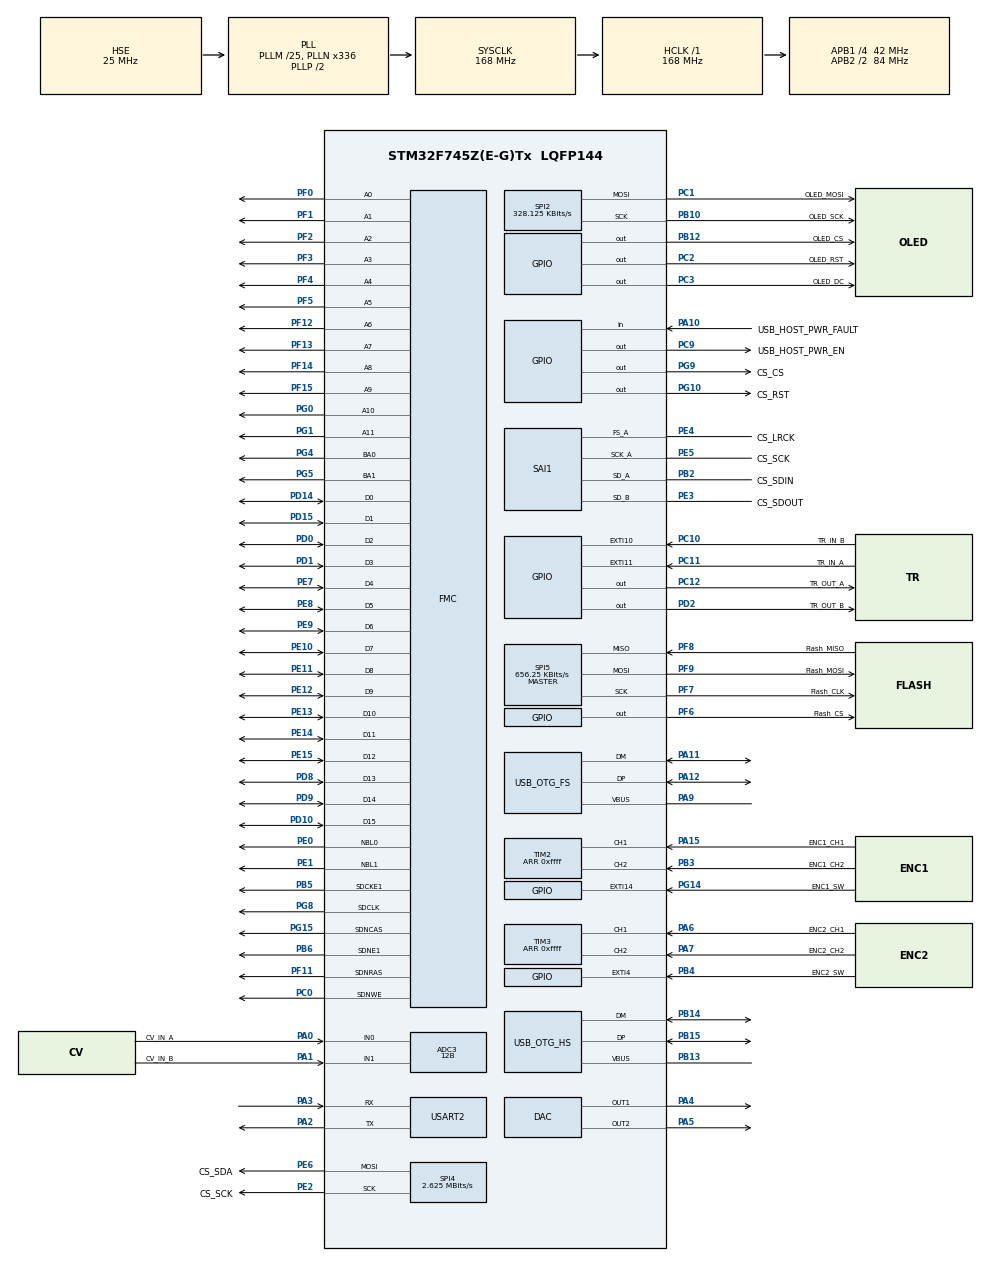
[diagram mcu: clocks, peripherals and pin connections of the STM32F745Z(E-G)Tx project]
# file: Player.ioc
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ADC3.Channel-0\#ChannelRegularConversion=ADC_CHANNEL_0
ADC3.Channel-1\#ChannelRegularConversion=ADC_CHANNEL_1
ADC3.Channel-2\#ChannelRegularConversion=ADC_CHANNEL_0
ADC3.Channel-3\#ChannelRegularConversion=ADC_CHANNEL_1
ADC3.ClockPrescaler=ADC_CLOCK_SYNC_PCLK_DIV8
ADC3.ContinuousConvMode=ENABLE
ADC3.DMAContinuousRequests=ENABLE
ADC3.DataAlign=ADC_DATAALIGN_RIGHT
ADC3.DiscontinuousConvMode=DISABLE
ADC3.EOCSelection=ADC_EOC_SEQ_CONV
ADC3.EnableAnalogWatchDog=false
ADC3.ExternalTrigConv=ADC_SOFTWARE_START
ADC3.ExternalTrigConvEdge=ADC_EXTERNALTRIGCONVEDGE_NONE
ADC3.InjNumberOfConversion=0
ADC3.NbrOfConversion=4
ADC3.NbrOfConversionFlag=1
ADC3.Rank-0\#ChannelRegularConversion=1
ADC3.Rank-1\#ChannelRegularConversion=2
ADC3.Rank-2\#ChannelRegularConversion=3
ADC3.Rank-3\#ChannelRegularConversion=4
ADC3.Resolution=ADC_RESOLUTION_12B
ADC3.SamplingTime-0\#ChannelRegularConversion=ADC_SAMPLETIME_144CYCLES
ADC3.SamplingTime-1\#ChannelRegularConversion=ADC_SAMPLETIME_144CYCLES
ADC3.SamplingTime-2\#ChannelRegularConversion=ADC_SAMPLETIME_144CYCLES
ADC3.SamplingTime-3\#ChannelRegularConversion=ADC_SAMPLETIME_144CYCLES
ADC3.ScanConvMode=ENABLE
DAC.DAC_OutputBuffer=DAC_OUTPUTBUFFER_DISABLE
DAC.DAC_OutputBuffer2=DAC_OUTPUTBUFFER_DISABLE
DAC.DAC_Trigger=DAC_TRIGGER_T6_TRGO
DAC.DAC_Trigger2=DAC_TRIGGER_T6_TRGO
Dma.ADC3.3.Direction=DMA_PERIPH_TO_MEMORY
Dma.ADC3.3.FIFOMode=DMA_FIFOMODE_DISABLE
Dma.ADC3.3.Instance=DMA2_Stream0
Dma.ADC3.3.MemDataAlignment=DMA_MDATAALIGN_HALFWORD
Dma.ADC3.3.MemInc=DMA_MINC_ENABLE
Dma.ADC3.3.Mode=DMA_CIRCULAR
Dma.ADC3.3.PeriphDataAlignment=DMA_PDATAALIGN_HALFWORD
Dma.ADC3.3.PeriphInc=DMA_PINC_DISABLE
Dma.ADC3.3.Priority=DMA_PRIORITY_LOW
Dma.DAC1.1.Direction=DMA_MEMORY_TO_PERIPH
Dma.DAC1.1.FIFOMode=DMA_FIFOMODE_DISABLE
Dma.DAC1.1.Instance=DMA1_Stream5
Dma.DAC1.1.MemDataAlignment=DMA_MDATAALIGN_HALFWORD
Dma.DAC1.1.MemInc=DMA_MINC_ENABLE
Dma.DAC1.1.Mode=DMA_NORMAL
Dma.DAC1.1.PeriphDataAlignment=DMA_PDATAALIGN_HALFWORD
Dma.DAC1.1.PeriphInc=DMA_PINC_DISABLE
Dma.DAC1.1.Priority=DMA_PRIORITY_LOW
Dma.DAC2.2.Direction=DMA_MEMORY_TO_PERIPH
Dma.DAC2.2.FIFOMode=DMA_FIFOMODE_DISABLE
Dma.DAC2.2.Instance=DMA1_Stream6
Dma.DAC2.2.MemDataAlignment=DMA_MDATAALIGN_HALFWORD
Dma.DAC2.2.MemInc=DMA_MINC_ENABLE
Dma.DAC2.2.Mode=DMA_NORMAL
Dma.DAC2.2.PeriphDataAlignment=DMA_PDATAALIGN_HALFWORD
Dma.DAC2.2.PeriphInc=DMA_PINC_DISABLE
Dma.DAC2.2.Priority=DMA_PRIORITY_LOW
Dma.Request0=SPI2_TX
Dma.Request1=DAC1
Dma.Request2=DAC2
Dma.Request3=ADC3
Dma.Request4=SAI1_A
Dma.Request5=SAI1_B
Dma.SAI1_A.4.Direction=DMA_MEMORY_TO_PERIPH
Dma.SAI1_A.4.FIFOMode=DMA_FIFOMODE_DISABLE
Dma.SAI1_A.4.Instance=DMA2_Stream1
Dma.SAI1_A.4.MemDataAlignment=DMA_MDATAALIGN_WORD
Dma.SAI1_A.4.MemInc=DMA_MINC_ENABLE
Dma.SAI1_A.4.Mode=DMA_CIRCULAR
Dma.SAI1_A.4.PeriphDataAlignment=DMA_PDATAALIGN_WORD
Dma.SAI1_A.4.PeriphInc=DMA_PINC_DISABLE
Dma.SAI1_A.4.Priority=DMA_PRIORITY_HIGH
Dma.SAI1_B.5.Direction=DMA_PERIPH_TO_MEMORY
Dma.SAI1_B.5.FIFOMode=DMA_FIFOMODE_DISABLE
Dma.SAI1_B.5.Instance=DMA2_Stream4
Dma.SAI1_B.5.MemDataAlignment=DMA_MDATAALIGN_WORD
Dma.SAI1_B.5.MemInc=DMA_MINC_ENABLE
Dma.SAI1_B.5.Mode=DMA_CIRCULAR
Dma.SAI1_B.5.PeriphDataAlignment=DMA_PDATAALIGN_WORD
Dma.SAI1_B.5.PeriphInc=DMA_PINC_DISABLE
Dma.SAI1_B.5.Priority=DMA_PRIORITY_HIGH
Dma.SPI2_TX.0.Direction=DMA_MEMORY_TO_PERIPH
Dma.SPI2_TX.0.FIFOMode=DMA_FIFOMODE_DISABLE
Dma.SPI2_TX.0.Instance=DMA1_Stream4
Dma.SPI2_TX.0.MemDataAlignment=DMA_MDATAALIGN_BYTE
Dma.SPI2_TX.0.MemInc=DMA_MINC_ENABLE
Dma.SPI2_TX.0.Mode=DMA_NORMAL
Dma.SPI2_TX.0.PeriphDataAlignment=DMA_PDATAALIGN_BYTE
Dma.SPI2_TX.0.PeriphInc=DMA_PINC_DISABLE
Dma.SPI2_TX.0.Priority=DMA_PRIORITY_LOW
FMC.CASLatency1=FMC_SDRAM_CAS_LATENCY_3
FMC.ExitSelfRefreshDelay1=6
FMC.LoadToActiveDelay1=2
FMC.RCDDelay1=2
FMC.RPDelay1=2
FMC.ReadBurst1=FMC_SDRAM_RBURST_ENABLE
FMC.ReadPipeDelay1=FMC_SDRAM_RPIPE_DELAY_0
FMC.RowCycleDelay1=6
FMC.SDClockPeriod1=FMC_SDRAM_CLOCK_PERIOD_2
FMC.SelfRefreshTime1=4
FMC.WriteRecoveryTime1=2
FREERTOS.MEMORY_ALLOCATION=2
FREERTOS.Tasks01=defaultTask,0,128,StartDefaultTask,Default
FREERTOS.configCHECK_FOR_STACK_OVERFLOW=1
FREERTOS.configUSE_MALLOC_FAILED_HOOK=1
FREERTOS.configUSE_MUTEXES=0
FREERTOS.configUSE_PREEMPTION=0
Mcu.Family=STM32F7
Mcu.Name=STM32F745Z(E-G)Tx
Mcu.Package=LQFP144
NVIC.DMA1_Stream4_IRQn=true\:5\:0\:false\:false\:true\:true\:true
NVIC.DMA1_Stream5_IRQn=true\:5\:0\:false\:false\:true\:true\:true
NVIC.DMA1_Stream6_IRQn=true\:5\:0\:false\:false\:true\:true\:true
NVIC.DMA2_Stream0_IRQn=true\:10\:0\:true\:false\:true\:true\:true
NVIC.DMA2_Stream1_IRQn=true\:5\:0\:false\:false\:true\:true\:true
NVIC.DMA2_Stream4_IRQn=true\:5\:0\:false\:false\:true\:true\:true
NVIC.EXTI15_10_IRQn=true\:10\:0\:true\:false\:true\:true\:true
NVIC.EXTI4_IRQn=true\:10\:0\:true\:false\:true\:true\:true
NVIC.OTG_FS_IRQn=true\:10\:0\:true\:false\:true\:true\:true
NVIC.OTG_HS_IRQn=true\:10\:0\:true\:false\:true\:true\:true
NVIC.PriorityGroup=NVIC_PRIORITYGROUP_4
NVIC.SPI2_IRQn=true\:5\:0\:false\:false\:true\:true\:true
NVIC.TIM2_IRQn=true\:10\:0\:true\:false\:true\:true\:true
NVIC.TIM3_IRQn=true\:10\:0\:true\:false\:true\:true\:true
PA0/WKUP.GPIO_Label=CV_IN_A
PA0/WKUP.Signal=ADCx_IN0
PA1.GPIO_Label=CV_IN_B
PA1.Signal=ADCx_IN1
PA10.GPIO_Label=USB_HOST_PWR_FAULT
PA10.Signal=GPIO_Input
PA11.Mode=Host_Only
PA11.Signal=USB_OTG_FS_DM
PA12.Mode=Host_Only
PA12.Signal=USB_OTG_FS_DP
PA13.Mode=Serial_Wire
PA13.Signal=SYS_JTMS-SWDIO
PA14.Mode=Serial_Wire
PA14.Signal=SYS_JTCK-SWCLK
PA15.GPIO_Label=ENC1_CH1
PA15.GPIO_PuPd=GPIO_PULLUP
PA15.Signal=S_TIM2_CH1_ETR
PA2.Mode=Asynchronous
PA2.Signal=USART2_TX
PA3.Mode=Asynchronous
PA3.Signal=USART2_RX
PA4.Signal=COMP_DAC1_group
PA5.Signal=COMP_DAC2_group
PA6.GPIO_Label=ENC2_CH1
PA6.GPIO_PuPd=GPIO_PULLUP
PA6.Signal=S_TIM3_CH1
PA7.GPIO_Label=ENC2_CH2
PA7.GPIO_PuPd=GPIO_PULLUP
PA7.Signal=S_TIM3_CH2
PA9.Mode=Activate_VBUS
PA9.Signal=USB_OTG_FS_VBUS
PB10.GPIO_Label=OLED_SCK
PB10.Mode=TX_Only_Simplex_Unidirect_Master
PB10.Signal=SPI2_SCK
PB12.GPIO_Label=OLED_CS
PB12.Signal=GPIO_Output
PB13.Mode=Activate_VBUS_FS
PB13.Signal=USB_OTG_HS_VBUS
PB14.Mode=Device_Only_FS
PB14.Signal=USB_OTG_HS_DM
PB15.Mode=Device_Only_FS
PB15.Signal=USB_OTG_HS_DP
PB2.GPIO_Label=CS_SDIN
PB2.Mode=SAI_A_AsyncSlave
PB2.Signal=SAI1_SD_A
PB3.GPIO_Label=ENC1_CH2
PB3.GPIO_PuPd=GPIO_PULLUP
PB3.Signal=S_TIM2_CH2
PB4.GPIO_Label=ENC2_SW
PB4.GPIO_ModeDefaultEXTI=GPIO_MODE_IT_FALLING
PB4.GPIO_PuPd=GPIO_PULLUP
PB4.Signal=GPXTI4
PB5.Mode=SdramChipSelect2_1
PB5.Signal=FMC_SDCKE1
PB6.Mode=SdramChipSelect2_1
PB6.Signal=FMC_SDNE1
PC0.Signal=FMC_SDNWE
PC1.GPIO_Label=OLED_MOSI
PC1.Mode=TX_Only_Simplex_Unidirect_Master
PC1.Signal=SPI2_MOSI
PC10.GPIO_Label=TR_IN_B
PC10.GPIO_ModeDefaultEXTI=GPIO_MODE_IT_RISING_FALLING
PC10.GPIO_PuPd=GPIO_PULLUP
PC10.Signal=GPXTI10
PC11.GPIO_Label=TR_IN_A
PC11.GPIO_ModeDefaultEXTI=GPIO_MODE_IT_RISING_FALLING
PC11.GPIO_PuPd=GPIO_PULLUP
PC11.Signal=GPXTI11
PC12.GPIO_Label=TR_OUT_A
PC12.Signal=GPIO_Output
PC2.GPIO_Label=OLED_RST
PC2.Signal=GPIO_Output
PC3.GPIO_Label=OLED_DC
PC3.Signal=GPIO_Output
PC9.GPIO_Label=USB_HOST_PWR_EN
PC9.Signal=GPIO_Output
PD0.Signal=FMC_D2_DA2
PD1.Signal=FMC_D3_DA3
PD10.Signal=FMC_D15_DA15
PD14.Signal=FMC_D0_DA0
PD15.Signal=FMC_D1_DA1
PD2.GPIO_Label=TR_OUT_B
PD2.Signal=GPIO_Output
PD8.Signal=FMC_D13_DA13
PD9.Signal=FMC_D14_DA14
PE0.Signal=FMC_NBL0
PE1.Signal=FMC_NBL1
PE10.Signal=FMC_D7_DA7
PE11.Signal=FMC_D8_DA8
PE12.Signal=FMC_D9_DA9
PE13.Signal=FMC_D10_DA10
PE14.Signal=FMC_D11_DA11
PE15.Signal=FMC_D12_DA12
PE2.GPIO_Label=CS_SCK
PE2.Mode=TX_Only_Simplex_Unidirect_Master
PE2.Signal=SPI4_SCK
PE3.GPIO_Label=CS_SDOUT
PE3.Mode=SAI_B_SyncSlave
PE3.Signal=SAI1_SD_B
PE4.GPIO_Label=CS_LRCK
PE4.Mode=SAI_A_AsyncSlave
PE4.Signal=SAI1_FS_A
PE5.GPIO_Label=CS_SCK
PE5.Mode=SAI_A_AsyncSlave
PE5.Signal=SAI1_SCK_A
PE6.GPIO_Label=CS_SDA
PE6.Mode=TX_Only_Simplex_Unidirect_Master
PE6.Signal=SPI4_MOSI
PE7.Signal=FMC_D4_DA4
PE8.Signal=FMC_D5_DA5
PE9.Signal=FMC_D6_DA6
PF0.Signal=FMC_A0
PF1.Signal=FMC_A1
PF11.Signal=FMC_SDNRAS
PF12.Signal=FMC_A6
PF13.Signal=FMC_A7
PF14.Signal=FMC_A8
PF15.Signal=FMC_A9
PF2.Signal=FMC_A2
PF3.Signal=FMC_A3
PF4.Signal=FMC_A4
PF5.Signal=FMC_A5
PF6.GPIO_Label=Flash_CS
PF6.Signal=GPIO_Output
PF7.GPIO_Label=Flash_CLK
PF7.Mode=Full_Duplex_Master
PF7.Signal=SPI5_SCK
PF8.GPIO_Label=Flash_MISO
PF8.Mode=Full_Duplex_Master
PF8.Signal=SPI5_MISO
PF9.GPIO_Label=Flash_MOSI
PF9.Mode=Full_Duplex_Master
PF9.Signal=SPI5_MOSI
PG0.Signal=FMC_A10
PG1.Signal=FMC_A11
PG10.GPIO_Label=CS_RST
PG10.Signal=GPIO_Output
PG14.GPIO_Label=ENC1_SW
PG14.GPIO_ModeDefaultEXTI=GPIO_MODE_IT_FALLING
PG14.GPIO_PuPd=GPIO_PULLUP
PG14.Signal=GPXTI14
PG15.Signal=FMC_SDNCAS
PG4.Signal=FMC_A14_BA0
PG5.Signal=FMC_A15_BA1
PG8.Signal=FMC_SDCLK
PG9.GPIO_Label=CS_CS
PG9.Signal=GPIO_Output
PH0/OSC_IN.Mode=HSE-External-Oscillator
PH0/OSC_IN.Signal=RCC_OSC_IN
PH1/OSC_OUT.Mode=HSE-External-Oscillator
PH1/OSC_OUT.Signal=RCC_OSC_OUT
ProjectManager.HeapSize=0x400
ProjectManager.StackSize=0x200
ProjectManager.TargetToolchain=MDK-ARM V4
RCC.AHBFreq_Value=168000000
RCC.APB1CLKDivider=RCC_HCLK_DIV4
RCC.APB1Freq_Value=42000000
RCC.APB1TimFreq_Value=84000000
RCC.APB2CLKDivider=RCC_HCLK_DIV2
RCC.APB2Freq_Value=84000000
RCC.APB2TimFreq_Value=168000000
RCC.CortexFreq_Value=168000000
RCC.HCLKFreq_Value=168000000
RCC.HSE_VALUE=25000000
RCC.HSI_VALUE=16000000
RCC.LSE_VALUE=32768
RCC.PLLM=25
RCC.PLLN=336
RCC.PLLQ=7
RCC.PLLSAIN=100
RCC.SYSCLKFreq_VALUE=168000000
RCC.SYSCLKSource=RCC_SYSCLKSOURCE_PLLCLK
RCC.USBFreq_Value=48000000
RCC.VCOOutputFreq_Value=336000000
SAI1.AudioMode-SAI_A_AsyncSlave=SAI_MODESLAVE_TX
SAI1.AudioMode-SAI_B_SyncSlave=SAI_MODESLAVE_RX
SAI1.BasicDataSize-SAI_A_AsyncSlave=SAI_PROTOCOL_DATASIZE_24BIT
SAI1.BasicDataSize-SAI_B_SyncSlave=SAI_PROTOCOL_DATASIZE_24BIT
SAI1.InitProtocol-SAI_A_AsyncSlave=Enable
SAI1.InitProtocol-SAI_B_SyncSlave=Enable
SAI1.Instance-SAI_A_AsyncSlave=SAI$Index_Block_A
SAI1.Instance-SAI_B_SyncSlave=SAI$Index_Block_B
SAI1.Synchro-SAI_A_AsyncSlave=SAI_ASYNCHRONOUS
SAI1.Synchro-SAI_B_SyncSlave=SAI_SYNCHRONOUS
SAI1.TriState-SAI_A_AsyncSlave=SAI_OUTPUT_NOTRELEASED
SAI1.VirtualMode-SAI_A_AsyncSlave=VM_SLAVE
SAI1.VirtualMode-SAI_B_SyncSlave=VM_SLAVE
SAI1.VirtualProtocol-SAI_A_BASIC=VM_BASIC_PROTOCOL
SAI1.VirtualProtocol-SAI_B_BASIC=VM_BASIC_PROTOCOL
SH.ADCx_IN0.0=ADC1_IN0
SH.ADCx_IN0.1=ADC3_IN0,IN0
SH.ADCx_IN1.0=ADC1_IN1
SH.ADCx_IN1.1=ADC3_IN1,IN1
SH.COMP_DAC1_group.0=DAC_OUT1,DAC_OUT1
SH.COMP_DAC2_group.0=DAC_OUT2,DAC_OUT2
SH.FMC_A0.0=FMC_A0,12b-sda1
SH.FMC_A1.0=FMC_A1,12b-sda1
SH.FMC_A10.0=FMC_A10,12b-sda1
SH.FMC_A11.0=FMC_A11,12b-sda1
SH.FMC_A14_BA0.0=FMC_BA0,FourSdramBanks1
SH.FMC_A15_BA1.0=FMC_BA1,FourSdramBanks1
SH.FMC_A2.0=FMC_A2,12b-sda1
SH.FMC_A3.0=FMC_A3,12b-sda1
SH.FMC_A4.0=FMC_A4,12b-sda1
SH.FMC_A5.0=FMC_A5,12b-sda1
SH.FMC_A6.0=FMC_A6,12b-sda1
SH.FMC_A7.0=FMC_A7,12b-sda1
SH.FMC_A8.0=FMC_A8,12b-sda1
SH.FMC_A9.0=FMC_A9,12b-sda1
SH.FMC_D0_DA0.0=FMC_D0,sd-16b-d1
SH.FMC_D10_DA10.0=FMC_D10,sd-16b-d1
SH.FMC_D11_DA11.0=FMC_D11,sd-16b-d1
SH.FMC_D12_DA12.0=FMC_D12,sd-16b-d1
SH.FMC_D13_DA13.0=FMC_D13,sd-16b-d1
SH.FMC_D14_DA14.0=FMC_D14,sd-16b-d1
SH.FMC_D15_DA15.0=FMC_D15,sd-16b-d1
SH.FMC_D1_DA1.0=FMC_D1,sd-16b-d1
SH.FMC_D2_DA2.0=FMC_D2,sd-16b-d1
SH.FMC_D3_DA3.0=FMC_D3,sd-16b-d1
SH.FMC_D4_DA4.0=FMC_D4,sd-16b-d1
SH.FMC_D5_DA5.0=FMC_D5,sd-16b-d1
SH.FMC_D6_DA6.0=FMC_D6,sd-16b-d1
SH.FMC_D7_DA7.0=FMC_D7,sd-16b-d1
SH.FMC_D8_DA8.0=FMC_D8,sd-16b-d1
SH.FMC_D9_DA9.0=FMC_D9,sd-16b-d1
SH.FMC_NBL0.0=FMC_NBL0,Sd2ByteEnable1
SH.FMC_NBL1.0=FMC_NBL1,Sd2ByteEnable1
SH.FMC_SDCLK.0=FMC_SDCLK,12b-sda1
SH.FMC_SDNCAS.0=FMC_SDNCAS,12b-sda1
SH.FMC_SDNRAS.0=FMC_SDNRAS,12b-sda1
SH.FMC_SDNWE.0=FMC_SDNWE,12b-sda1
SH.S_TIM2_CH1_ETR.0=TIM2_CH1,Encoder_Interface
SH.S_TIM2_CH2.0=TIM2_CH2,Encoder_Interface
SH.S_TIM3_CH1.0=TIM3_CH1,Encoder_Interface
SH.S_TIM3_CH2.0=TIM3_CH2,Encoder_Interface
SPI2.BaudRatePrescaler=SPI_BAUDRATEPRESCALER_128
SPI2.CalculateBaudRate=328.125 KBits/s
SPI2.DataSize=SPI_DATASIZE_8BIT
SPI2.Direction=SPI_DIRECTION_2LINES
SPI2.Mode=SPI_MODE_MASTER
SPI2.VirtualType=VM_MASTER
SPI4.BaudRatePrescaler=SPI_BAUDRATEPRESCALER_32
SPI4.CalculateBaudRate=2.625 MBits/s
SPI4.DataSize=SPI_DATASIZE_8BIT
SPI4.Direction=SPI_DIRECTION_2LINES
SPI4.Mode=SPI_MODE_MASTER
SPI4.NSSPMode=SPI_NSS_PULSE_DISABLE
SPI4.VirtualType=VM_MASTER
SPI5.BaudRatePrescaler=SPI_BAUDRATEPRESCALER_128
SPI5.CalculateBaudRate=656.25 KBits/s
SPI5.DataSize=SPI_DATASIZE_8BIT
SPI5.Direction=SPI_DIRECTION_2LINES
SPI5.Mode=SPI_MODE_MASTER
SPI5.VirtualType=VM_MASTER
TIM2.EncoderMode=TIM_ENCODERMODE_TI12
TIM2.Period=0xffff
TIM3.EncoderMode=TIM_ENCODERMODE_TI12
TIM3.Period=0xffff
TIM6.Period=8
TIM6.Prescaler=3500
TIM6.TIM_MasterOutputTrigger=TIM_TRGO_UPDATE
USART2.VirtualMode-Asynchronous=VM_ASYNC
USART2.WordLength=WORDLENGTH_8B
USB_DEVICE.CLASS_NAME_HS=AUDIO
USB_DEVICE.MANUFACTURER_STRING-AUDIO_HS=Rebel Technology
USB_DEVICE.PID_AUDIO_HS=0xDADA
USB_DEVICE.PRODUCT_STRING_AUDIO_HS=OWL-MIDI
USB_DEVICE.SERIALNUMBER_STRING_AUDIO_HS=00000000010E
USB_DEVICE.USBD_AUDIO_FREQ-AUDIO_HS=48000
USB_DEVICE.USBD_LPM_ENABLED-AUDIO_HS=0
USB_DEVICE.VID-AUDIO_HS=0x1209
USB_DEVICE.VirtualMode-AUDIO_HS=Audio
USB_DEVICE.VirtualModeHS=Audio_HS
USB_HOST.USBH_HandleTypeDef-AUDIO_FS=hUsbHostFS
USB_HOST.VirtualModeFS=Audio
USB_OTG_FS.VirtualMode=Host_Only
USB_OTG_FS.phy_itface=HCD_PHY_EMBEDDED
USB_OTG_HS.VirtualMode-Device_Only_FS=Device_Only_FS
VP_FREERTOS_VS_ENABLE.Mode=Enabled
VP_SAI1_VP_$IpInstance_SAIA_SAI_BASIC.Mode=SAI_A_BASIC
VP_SAI1_VP_$IpInstance_SAIB_SAI_BASIC.Mode=SAI_B_BASIC
VP_TIM6_VS_ClockSourceINT.Mode=Enable_Timer
VP_USB_DEVICE_VS_USB_DEVICE_AUDIO_HS.Mode=AUDIO_HS
VP_USB_HOST_VS_USB_HOST_AUDIO_FS.Mode=AUDIO_FS
board=Player

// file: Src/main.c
/**
  ******************************************************************************
  * File Name          : main.c
  * Description        : Main program body
  ******************************************************************************
  * This notice applies to any and all portions of this file
  * that are not between comment pairs USER CODE BEGIN and
  * USER CODE END. Other portions of this file, whether
  * inserted by the user or by software development tools
  * are owned by their respective copyright owners.
  *
  * Copyright (c) 2017 STMicroelectronics International N.V.
  * All rights reserved.
  *
  * Redistribution and use in source and binary forms, with or without
  * modification, are permitted, provided that the following conditions are met:
  *
  * 1. Redistribution of source code must retain the above copyright notice,
  *    this list of conditions and the following disclaimer.
  * 2. Redistributions in binary form must reproduce the above copyright notice,
  *    this list of conditions and the following disclaimer in the documentation
  *    and/or other materials provided with the distribution.
  * 3. Neither the name of STMicroelectronics nor the names of other
  *    contributors to this software may be used to endorse or promote products
  *    derived from this software without specific written permission.
  * 4. This software, including modifications and/or derivative works of this
  *    software, must execute solely and exclusively on microcontroller or
  *    microprocessor devices manufactured by or for STMicroelectronics.
  * 5. Redistribution and use of this software other than as permitted under
  *    this license is void and will automatically terminate your rights under
  *    this license.
  *
  * THIS SOFTWARE IS PROVIDED BY STMICROELECTRONICS AND CONTRIBUTORS "AS IS"
  * AND ANY EXPRESS, IMPLIED OR STATUTORY WARRANTIES, INCLUDING, BUT NOT
  * LIMITED TO, THE IMPLIED WARRANTIES OF MERCHANTABILITY, FITNESS FOR A
  * PARTICULAR PURPOSE AND NON-INFRINGEMENT OF THIRD PARTY INTELLECTUAL PROPERTY
  * RIGHTS ARE DISCLAIMED TO THE FULLEST EXTENT PERMITTED BY LAW. IN NO EVENT
  * SHALL STMICROELECTRONICS OR CONTRIBUTORS BE LIABLE FOR ANY DIRECT, INDIRECT,
  * INCIDENTAL, SPECIAL, EXEMPLARY, OR CONSEQUENTIAL DAMAGES (INCLUDING, BUT NOT
  * LIMITED TO, PROCUREMENT OF SUBSTITUTE GOODS OR SERVICES; LOSS OF USE, DATA,
  * OR PROFITS; OR BUSINESS INTERRUPTION) HOWEVER CAUSED AND ON ANY THEORY OF
  * LIABILITY, WHETHER IN CONTRACT, STRICT LIABILITY, OR TORT (INCLUDING
  * NEGLIGENCE OR OTHERWISE) ARISING IN ANY WAY OUT OF THE USE OF THIS SOFTWARE,
  * EVEN IF ADVISED OF THE POSSIBILITY OF SUCH DAMAGE.
  *
  ******************************************************************************
  */
#include "main.h"
#include "stm32f7xx_hal.h"
#include "cmsis_os.h"
#include "usb_device.h"
#include "usb_host.h"

/* USER CODE BEGIN Includes */
#include "HAL_Triggers.h"
#include "HAL_Encoders.h"
#include "HAL_CV_IO.h"
#include "sdram.h"
/* USER CODE END Includes */

ADC_HandleTypeDef hadc3;
DMA_HandleTypeDef hdma_adc3;

DAC_HandleTypeDef hdac;
DMA_HandleTypeDef hdma_dac1;
DMA_HandleTypeDef hdma_dac2;

SAI_HandleTypeDef hsai_BlockA1;
SAI_HandleTypeDef hsai_BlockB1;
DMA_HandleTypeDef hdma_sai1_a;
DMA_HandleTypeDef hdma_sai1_b;

SPI_HandleTypeDef hspi2;
SPI_HandleTypeDef hspi4;
SPI_HandleTypeDef hspi5;
DMA_HandleTypeDef hdma_spi2_tx;

TIM_HandleTypeDef htim2;
TIM_HandleTypeDef htim3;
TIM_HandleTypeDef htim6;

UART_HandleTypeDef huart2;

SDRAM_HandleTypeDef hsdram1;

osThreadId defaultTaskHandle;

/* USER CODE BEGIN PV */
/* Private variables ---------------------------------------------------------*/

/* USER CODE END PV */

void SystemClock_Config(void);
static void MX_GPIO_Init(void);
static void MX_DMA_Init(void);
static void MX_DAC_Init(void);
static void MX_FMC_Init(void);
static void MX_SAI1_Init(void);
static void MX_SPI2_Init(void);
static void MX_SPI5_Init(void);
static void MX_TIM2_Init(void);
static void MX_TIM3_Init(void);
static void MX_USART2_UART_Init(void);
static void MX_SPI4_Init(void);
static void MX_TIM6_Init(void);
static void MX_ADC3_Init(void);
void StartDefaultTask(void const * argument);

/* USER CODE BEGIN PFP */
/* Private function prototypes -----------------------------------------------*/

void setup(void);
void loop(void);
void MX_USB_HOST_Process(void);

/* USER CODE END PFP */

int main(void)
{

  /* USER CODE BEGIN 1 */
  /* Configure the MPU attributes as Write Back */
  MPU_Config();

  /* USER CODE END 1 */

  /* MCU Configuration----------------------------------------------------------*/

  /* Reset of all peripherals, Initializes the Flash interface and the Systick. */
  HAL_Init();

  /* Configure the system clock */
  SystemClock_Config();

  /* Initialize all configured peripherals */
  MX_GPIO_Init();
  MX_DMA_Init();
  MX_DAC_Init();
  MX_FMC_Init();
  MX_SAI1_Init();
  MX_SPI2_Init();
  MX_SPI5_Init();
  MX_TIM2_Init();
  MX_TIM3_Init();
  MX_USART2_UART_Init();
  MX_SPI4_Init();
  MX_TIM6_Init();
  MX_ADC3_Init();

  /* USER CODE BEGIN 2 */
  HAL_SAI_DeInit(&hsai_BlockA1);
  HAL_SAI_DeInit(&hsai_BlockB1);
  hsai_BlockA1.Instance = SAI1_Block_A;
  hsai_BlockA1.Init.AudioMode = SAI_MODESLAVE_TX;
  hsai_BlockA1.Init.Synchro = SAI_ASYNCHRONOUS;
  hsai_BlockA1.Init.OutputDrive = SAI_OUTPUTDRIVE_DISABLE;
  hsai_BlockA1.Init.FIFOThreshold = SAI_FIFOTHRESHOLD_EMPTY;
  hsai_BlockA1.Init.SynchroExt = SAI_SYNCEXT_DISABLE;
  hsai_BlockA1.Init.MonoStereoMode = SAI_STEREOMODE;
  hsai_BlockA1.Init.CompandingMode = SAI_NOCOMPANDING;
  hsai_BlockA1.Init.TriState = SAI_OUTPUT_NOTRELEASED;
  if (HAL_SAI_InitProtocol(&hsai_BlockA1, SAI_I2S_STANDARD, SAI_PROTOCOL_DATASIZE_24BIT, 2) != HAL_OK)
    Error_Handler();
  hsai_BlockB1.Instance = SAI1_Block_B;
  hsai_BlockB1.Init.AudioMode = SAI_MODESLAVE_RX;
  hsai_BlockB1.Init.Synchro = SAI_SYNCHRONOUS;
  hsai_BlockB1.Init.OutputDrive = SAI_OUTPUTDRIVE_DISABLE;
  hsai_BlockB1.Init.FIFOThreshold = SAI_FIFOTHRESHOLD_EMPTY;
  hsai_BlockB1.Init.SynchroExt = SAI_SYNCEXT_DISABLE;
  hsai_BlockB1.Init.MonoStereoMode = SAI_STEREOMODE;
  hsai_BlockB1.Init.CompandingMode = SAI_NOCOMPANDING;
  hsai_BlockB1.Init.TriState = SAI_OUTPUT_NOTRELEASED;
  if (HAL_SAI_InitProtocol(&hsai_BlockB1, SAI_I2S_STANDARD, SAI_PROTOCOL_DATASIZE_24BIT, 2) != HAL_OK)
    Error_Handler();

  /* Program the SDRAM external device */
  SDRAM_Initialization_Sequence(&hsdram1);

  /* USER CODE END 2 */

  /* Create the thread(s) */
  /* definition and creation of defaultTask */
  osThreadDef(defaultTask, StartDefaultTask, osPriorityNormal, 0, 128);
  defaultTaskHandle = osThreadCreate(osThread(defaultTask), NULL);

  /* Start scheduler */
  osKernelStart();

  /* We should never get here as control is now taken by the scheduler */

  /* Infinite loop */
  while (1)
  {

  }

}

/** System Clock Configuration
*/
void SystemClock_Config(void)
{

  RCC_OscInitTypeDef RCC_OscInitStruct;
  RCC_ClkInitTypeDef RCC_ClkInitStruct;
  RCC_PeriphCLKInitTypeDef PeriphClkInitStruct;

    /**Configure the main internal regulator output voltage
    */
  __HAL_RCC_PWR_CLK_ENABLE();

  __HAL_PWR_VOLTAGESCALING_CONFIG(PWR_REGULATOR_VOLTAGE_SCALE2);

    /**Initializes the CPU, AHB and APB busses clocks
    */
  RCC_OscInitStruct.OscillatorType = RCC_OSCILLATORTYPE_HSE;
  RCC_OscInitStruct.HSEState = RCC_HSE_ON;
  RCC_OscInitStruct.PLL.PLLState = RCC_PLL_ON;
  RCC_OscInitStruct.PLL.PLLSource = RCC_PLLSOURCE_HSE;
  RCC_OscInitStruct.PLL.PLLM = 25;
  RCC_OscInitStruct.PLL.PLLN = 336;
  RCC_OscInitStruct.PLL.PLLP = RCC_PLLP_DIV2;
  RCC_OscInitStruct.PLL.PLLQ = 7;
  if (HAL_RCC_OscConfig(&RCC_OscInitStruct) != HAL_OK)
  {
    _Error_Handler(__FILE__, __LINE__);
  }

    /**Initializes the CPU, AHB and APB busses clocks
    */
  RCC_ClkInitStruct.ClockType = RCC_CLOCKTYPE_HCLK|RCC_CLOCKTYPE_SYSCLK
                              |RCC_CLOCKTYPE_PCLK1|RCC_CLOCKTYPE_PCLK2;
  RCC_ClkInitStruct.SYSCLKSource = RCC_SYSCLKSOURCE_PLLCLK;
  RCC_ClkInitStruct.AHBCLKDivider = RCC_SYSCLK_DIV1;
  RCC_ClkInitStruct.APB1CLKDivider = RCC_HCLK_DIV4;
  RCC_ClkInitStruct.APB2CLKDivider = RCC_HCLK_DIV2;

  if (HAL_RCC_ClockConfig(&RCC_ClkInitStruct, FLASH_LATENCY_5) != HAL_OK)
  {
    _Error_Handler(__FILE__, __LINE__);
  }

  PeriphClkInitStruct.PeriphClockSelection = RCC_PERIPHCLK_USART2|RCC_PERIPHCLK_SAI1
                              |RCC_PERIPHCLK_CLK48;
  PeriphClkInitStruct.PLLSAI.PLLSAIN = 100;
  PeriphClkInitStruct.PLLSAI.PLLSAIR = 2;
  PeriphClkInitStruct.PLLSAI.PLLSAIQ = 2;
  PeriphClkInitStruct.PLLSAI.PLLSAIP = RCC_PLLSAIP_DIV2;
  PeriphClkInitStruct.PLLSAIDivQ = 1;
  PeriphClkInitStruct.PLLSAIDivR = RCC_PLLSAIDIVR_2;
  PeriphClkInitStruct.Sai1ClockSelection = RCC_SAI1CLKSOURCE_PLLSAI;
  PeriphClkInitStruct.Usart2ClockSelection = RCC_USART2CLKSOURCE_PCLK1;
  PeriphClkInitStruct.Clk48ClockSelection = RCC_CLK48SOURCE_PLL;
  if (HAL_RCCEx_PeriphCLKConfig(&PeriphClkInitStruct) != HAL_OK)
  {
    _Error_Handler(__FILE__, __LINE__);
  }

    /**Configure the Systick interrupt time
    */
  HAL_SYSTICK_Config(HAL_RCC_GetHCLKFreq()/1000);

    /**Configure the Systick
    */
  HAL_SYSTICK_CLKSourceConfig(SYSTICK_CLKSOURCE_HCLK);

  /* SysTick_IRQn interrupt configuration */
  HAL_NVIC_SetPriority(SysTick_IRQn, 15, 0);
}

/* ADC3 init function */
static void MX_ADC3_Init(void)
{

  ADC_ChannelConfTypeDef sConfig;

    /**Configure the global features of the ADC (Clock, Resolution, Data Alignment and number of conversion)
    */
  hadc3.Instance = ADC3;
  hadc3.Init.ClockPrescaler = ADC_CLOCK_SYNC_PCLK_DIV8;
  hadc3.Init.Resolution = ADC_RESOLUTION_12B;
  hadc3.Init.ScanConvMode = ENABLE;
  hadc3.Init.ContinuousConvMode = ENABLE;
  hadc3.Init.DiscontinuousConvMode = DISABLE;
  hadc3.Init.ExternalTrigConvEdge = ADC_EXTERNALTRIGCONVEDGE_NONE;
  hadc3.Init.ExternalTrigConv = ADC_SOFTWARE_START;
  hadc3.Init.DataAlign = ADC_DATAALIGN_RIGHT;
  hadc3.Init.NbrOfConversion = 4;
  hadc3.Init.DMAContinuousRequests = ENABLE;
  hadc3.Init.EOCSelection = ADC_EOC_SEQ_CONV;
  if (HAL_ADC_Init(&hadc3) != HAL_OK)
  {
    _Error_Handler(__FILE__, __LINE__);
  }

    /**Configure for the selected ADC regular channel its corresponding rank in the sequencer and its sample time.
    */
  sConfig.Channel = ADC_CHANNEL_0;
  sConfig.Rank = 1;
  sConfig.SamplingTime = ADC_SAMPLETIME_144CYCLES;
  if (HAL_ADC_ConfigChannel(&hadc3, &sConfig) != HAL_OK)
  {
    _Error_Handler(__FILE__, __LINE__);
  }

    /**Configure for the selected ADC regular channel its corresponding rank in the sequencer and its sample time.
    */
  sConfig.Channel = ADC_CHANNEL_1;
  sConfig.Rank = 2;
  if (HAL_ADC_ConfigChannel(&hadc3, &sConfig) != HAL_OK)
  {
    _Error_Handler(__FILE__, __LINE__);
  }

    /**Configure for the selected ADC regular channel its corresponding rank in the sequencer and its sample time.
    */
  sConfig.Channel = ADC_CHANNEL_0;
  sConfig.Rank = 3;
  if (HAL_ADC_ConfigChannel(&hadc3, &sConfig) != HAL_OK)
  {
    _Error_Handler(__FILE__, __LINE__);
  }

    /**Configure for the selected ADC regular channel its corresponding rank in the sequencer and its sample time.
    */
  sConfig.Channel = ADC_CHANNEL_1;
  sConfig.Rank = 4;
  if (HAL_ADC_ConfigChannel(&hadc3, &sConfig) != HAL_OK)
  {
    _Error_Handler(__FILE__, __LINE__);
  }

}

/* DAC init function */
static void MX_DAC_Init(void)
{

  DAC_ChannelConfTypeDef sConfig;

    /**DAC Initialization
    */
  hdac.Instance = DAC;
  if (HAL_DAC_Init(&hdac) != HAL_OK)
  {
    _Error_Handler(__FILE__, __LINE__);
  }

    /**DAC channel OUT1 config
    */
  sConfig.DAC_Trigger = DAC_TRIGGER_T6_TRGO;
  sConfig.DAC_OutputBuffer = DAC_OUTPUTBUFFER_DISABLE;
  if (HAL_DAC_ConfigChannel(&hdac, &sConfig, DAC_CHANNEL_1) != HAL_OK)
  {
    _Error_Handler(__FILE__, __LINE__);
  }

    /**DAC channel OUT2 config
    */
  if (HAL_DAC_ConfigChannel(&hdac, &sConfig, DAC_CHANNEL_2) != HAL_OK)
  {
    _Error_Handler(__FILE__, __LINE__);
  }

}

/* SAI1 init function */
static void MX_SAI1_Init(void)
{

  hsai_BlockA1.Instance = SAI1_Block_A;
  hsai_BlockA1.Init.AudioMode = SAI_MODESLAVE_TX;
  hsai_BlockA1.Init.Synchro = SAI_ASYNCHRONOUS;
  hsai_BlockA1.Init.OutputDrive = SAI_OUTPUTDRIVE_DISABLE;
  hsai_BlockA1.Init.FIFOThreshold = SAI_FIFOTHRESHOLD_EMPTY;
  hsai_BlockA1.Init.SynchroExt = SAI_SYNCEXT_DISABLE;
  hsai_BlockA1.Init.MonoStereoMode = SAI_STEREOMODE;
  hsai_BlockA1.Init.CompandingMode = SAI_NOCOMPANDING;
  hsai_BlockA1.Init.TriState = SAI_OUTPUT_NOTRELEASED;
  if (HAL_SAI_InitProtocol(&hsai_BlockA1, SAI_I2S_STANDARD, SAI_PROTOCOL_DATASIZE_24BIT, 2) != HAL_OK)
  {
    _Error_Handler(__FILE__, __LINE__);
  }

  hsai_BlockB1.Instance = SAI1_Block_B;
  hsai_BlockB1.Init.AudioMode = SAI_MODESLAVE_RX;
  hsai_BlockB1.Init.Synchro = SAI_SYNCHRONOUS;
  hsai_BlockB1.Init.OutputDrive = SAI_OUTPUTDRIVE_DISABLE;
  hsai_BlockB1.Init.FIFOThreshold = SAI_FIFOTHRESHOLD_EMPTY;
  hsai_BlockB1.Init.SynchroExt = SAI_SYNCEXT_DISABLE;
  hsai_BlockB1.Init.MonoStereoMode = SAI_STEREOMODE;
  hsai_BlockB1.Init.CompandingMode = SAI_NOCOMPANDING;
  hsai_BlockB1.Init.TriState = SAI_OUTPUT_NOTRELEASED;
  if (HAL_SAI_InitProtocol(&hsai_BlockB1, SAI_I2S_STANDARD, SAI_PROTOCOL_DATASIZE_24BIT, 2) != HAL_OK)
  {
    _Error_Handler(__FILE__, __LINE__);
  }

}

/* SPI2 init function */
static void MX_SPI2_Init(void)
{

  /* SPI2 parameter configuration*/
  hspi2.Instance = SPI2;
  hspi2.Init.Mode = SPI_MODE_MASTER;
  hspi2.Init.Direction = SPI_DIRECTION_2LINES;
  hspi2.Init.DataSize = SPI_DATASIZE_8BIT;
  hspi2.Init.CLKPolarity = SPI_POLARITY_LOW;
  hspi2.Init.CLKPhase = SPI_PHASE_1EDGE;
  hspi2.Init.NSS = SPI_NSS_SOFT;
  hspi2.Init.BaudRatePrescaler = SPI_BAUDRATEPRESCALER_128;
  hspi2.Init.FirstBit = SPI_FIRSTBIT_MSB;
  hspi2.Init.TIMode = SPI_TIMODE_DISABLE;
  hspi2.Init.CRCCalculation = SPI_CRCCALCULATION_DISABLE;
  hspi2.Init.CRCPolynomial = 7;
  hspi2.Init.CRCLength = SPI_CRC_LENGTH_DATASIZE;
  hspi2.Init.NSSPMode = SPI_NSS_PULSE_ENABLE;
  if (HAL_SPI_Init(&hspi2) != HAL_OK)
  {
    _Error_Handler(__FILE__, __LINE__);
  }

}

/* SPI4 init function */
static void MX_SPI4_Init(void)
{

  /* SPI4 parameter configuration*/
  hspi4.Instance = SPI4;
  hspi4.Init.Mode = SPI_MODE_MASTER;
  hspi4.Init.Direction = SPI_DIRECTION_2LINES;
  hspi4.Init.DataSize = SPI_DATASIZE_8BIT;
  hspi4.Init.CLKPolarity = SPI_POLARITY_LOW;
  hspi4.Init.CLKPhase = SPI_PHASE_1EDGE;
  hspi4.Init.NSS = SPI_NSS_SOFT;
  hspi4.Init.BaudRatePrescaler = SPI_BAUDRATEPRESCALER_32;
  hspi4.Init.FirstBit = SPI_FIRSTBIT_MSB;
  hspi4.Init.TIMode = SPI_TIMODE_DISABLE;
  hspi4.Init.CRCCalculation = SPI_CRCCALCULATION_DISABLE;
  hspi4.Init.CRCPolynomial = 7;
  hspi4.Init.CRCLength = SPI_CRC_LENGTH_DATASIZE;
  hspi4.Init.NSSPMode = SPI_NSS_PULSE_DISABLE;
  if (HAL_SPI_Init(&hspi4) != HAL_OK)
  {
    _Error_Handler(__FILE__, __LINE__);
  }

}

/* SPI5 init function */
static void MX_SPI5_Init(void)
{

  /* SPI5 parameter configuration*/
  hspi5.Instance = SPI5;
  hspi5.Init.Mode = SPI_MODE_MASTER;
  hspi5.Init.Direction = SPI_DIRECTION_2LINES;
  hspi5.Init.DataSize = SPI_DATASIZE_8BIT;
  hspi5.Init.CLKPolarity = SPI_POLARITY_LOW;
  hspi5.Init.CLKPhase = SPI_PHASE_1EDGE;
  hspi5.Init.NSS = SPI_NSS_SOFT;
  hspi5.Init.BaudRatePrescaler = SPI_BAUDRATEPRESCALER_128;
  hspi5.Init.FirstBit = SPI_FIRSTBIT_MSB;
  hspi5.Init.TIMode = SPI_TIMODE_DISABLE;
  hspi5.Init.CRCCalculation = SPI_CRCCALCULATION_DISABLE;
  hspi5.Init.CRCPolynomial = 7;
  hspi5.Init.CRCLength = SPI_CRC_LENGTH_DATASIZE;
  hspi5.Init.NSSPMode = SPI_NSS_PULSE_ENABLE;
  if (HAL_SPI_Init(&hspi5) != HAL_OK)
  {
    _Error_Handler(__FILE__, __LINE__);
  }

}

/* TIM2 init function */
static void MX_TIM2_Init(void)
{

  TIM_Encoder_InitTypeDef sConfig;
  TIM_MasterConfigTypeDef sMasterConfig;

  htim2.Instance = TIM2;
  htim2.Init.Prescaler = 0;
  htim2.Init.CounterMode = TIM_COUNTERMODE_UP;
  htim2.Init.Period = 0xffff;
  htim2.Init.ClockDivision = TIM_CLOCKDIVISION_DIV1;
  htim2.Init.AutoReloadPreload = TIM_AUTORELOAD_PRELOAD_DISABLE;
  sConfig.EncoderMode = TIM_ENCODERMODE_TI12;
  sConfig.IC1Polarity = TIM_ICPOLARITY_RISING;
  sConfig.IC1Selection = TIM_ICSELECTION_DIRECTTI;
  sConfig.IC1Prescaler = TIM_ICPSC_DIV1;
  sConfig.IC1Filter = 0;
  sConfig.IC2Polarity = TIM_ICPOLARITY_RISING;
  sConfig.IC2Selection = TIM_ICSELECTION_DIRECTTI;
  sConfig.IC2Prescaler = TIM_ICPSC_DIV1;
  sConfig.IC2Filter = 0;
  if (HAL_TIM_Encoder_Init(&htim2, &sConfig) != HAL_OK)
  {
    _Error_Handler(__FILE__, __LINE__);
  }

  sMasterConfig.MasterOutputTrigger = TIM_TRGO_RESET;
  sMasterConfig.MasterSlaveMode = TIM_MASTERSLAVEMODE_DISABLE;
  if (HAL_TIMEx_MasterConfigSynchronization(&htim2, &sMasterConfig) != HAL_OK)
  {
    _Error_Handler(__FILE__, __LINE__);
  }

}

/* TIM3 init function */
static void MX_TIM3_Init(void)
{

  TIM_Encoder_InitTypeDef sConfig;
  TIM_MasterConfigTypeDef sMasterConfig;

  htim3.Instance = TIM3;
  htim3.Init.Prescaler = 0;
  htim3.Init.CounterMode = TIM_COUNTERMODE_UP;
  htim3.Init.Period = 0xffff;
  htim3.Init.ClockDivision = TIM_CLOCKDIVISION_DIV1;
  htim3.Init.AutoReloadPreload = TIM_AUTORELOAD_PRELOAD_DISABLE;
  sConfig.EncoderMode = TIM_ENCODERMODE_TI12;
  sConfig.IC1Polarity = TIM_ICPOLARITY_RISING;
  sConfig.IC1Selection = TIM_ICSELECTION_DIRECTTI;
  sConfig.IC1Prescaler = TIM_ICPSC_DIV1;
  sConfig.IC1Filter = 0;
  sConfig.IC2Polarity = TIM_ICPOLARITY_RISING;
  sConfig.IC2Selection = TIM_ICSELECTION_DIRECTTI;
  sConfig.IC2Prescaler = TIM_ICPSC_DIV1;
  sConfig.IC2Filter = 0;
  if (HAL_TIM_Encoder_Init(&htim3, &sConfig) != HAL_OK)
  {
    _Error_Handler(__FILE__, __LINE__);
  }

  sMasterConfig.MasterOutputTrigger = TIM_TRGO_RESET;
  sMasterConfig.MasterSlaveMode = TIM_MASTERSLAVEMODE_DISABLE;
  if (HAL_TIMEx_MasterConfigSynchronization(&htim3, &sMasterConfig) != HAL_OK)
  {
    _Error_Handler(__FILE__, __LINE__);
  }

}

/* TIM6 init function */
static void MX_TIM6_Init(void)
{

  TIM_MasterConfigTypeDef sMasterConfig;

  htim6.Instance = TIM6;
  htim6.Init.Prescaler = 3500;
  htim6.Init.CounterMode = TIM_COUNTERMODE_UP;
  htim6.Init.Period = 8;
  htim6.Init.AutoReloadPreload = TIM_AUTORELOAD_PRELOAD_DISABLE;
  if (HAL_TIM_Base_Init(&htim6) != HAL_OK)
  {
    _Error_Handler(__FILE__, __LINE__);
  }

  sMasterConfig.MasterOutputTrigger = TIM_TRGO_UPDATE;
  sMasterConfig.MasterSlaveMode = TIM_MASTERSLAVEMODE_DISABLE;
  if (HAL_TIMEx_MasterConfigSynchronization(&htim6, &sMasterConfig) != HAL_OK)
  {
    _Error_Handler(__FILE__, __LINE__);
  }

}

/* USART2 init function */
static void MX_USART2_UART_Init(void)
{

  huart2.Instance = USART2;
  huart2.Init.BaudRate = 115200;
  huart2.Init.WordLength = UART_WORDLENGTH_8B;
  huart2.Init.StopBits = UART_STOPBITS_1;
  huart2.Init.Parity = UART_PARITY_NONE;
  huart2.Init.Mode = UART_MODE_TX_RX;
  huart2.Init.HwFlowCtl = UART_HWCONTROL_NONE;
  huart2.Init.OverSampling = UART_OVERSAMPLING_16;
  huart2.Init.OneBitSampling = UART_ONE_BIT_SAMPLE_DISABLE;
  huart2.AdvancedInit.AdvFeatureInit = UART_ADVFEATURE_NO_INIT;
  if (HAL_UART_Init(&huart2) != HAL_OK)
  {
    _Error_Handler(__FILE__, __LINE__);
  }

}

static void MX_DMA_Init(void)
{
  /* DMA controller clock enable */
  __HAL_RCC_DMA1_CLK_ENABLE();
  __HAL_RCC_DMA2_CLK_ENABLE();

  /* DMA interrupt init */
  /* DMA1_Stream4_IRQn interrupt configuration */
  HAL_NVIC_SetPriority(DMA1_Stream4_IRQn, 5, 0);
  HAL_NVIC_EnableIRQ(DMA1_Stream4_IRQn);
  /* DMA1_Stream5_IRQn interrupt configuration */
  HAL_NVIC_SetPriority(DMA1_Stream5_IRQn, 5, 0);
  HAL_NVIC_EnableIRQ(DMA1_Stream5_IRQn);
  /* DMA1_Stream6_IRQn interrupt configuration */
  HAL_NVIC_SetPriority(DMA1_Stream6_IRQn, 5, 0);
  HAL_NVIC_EnableIRQ(DMA1_Stream6_IRQn);
  /* DMA2_Stream0_IRQn interrupt configuration */
  HAL_NVIC_SetPriority(DMA2_Stream0_IRQn, 10, 0);
  HAL_NVIC_EnableIRQ(DMA2_Stream0_IRQn);
  /* DMA2_Stream1_IRQn interrupt configuration */
  HAL_NVIC_SetPriority(DMA2_Stream1_IRQn, 5, 0);
  HAL_NVIC_EnableIRQ(DMA2_Stream1_IRQn);
  /* DMA2_Stream4_IRQn interrupt configuration */
  HAL_NVIC_SetPriority(DMA2_Stream4_IRQn, 5, 0);
  HAL_NVIC_EnableIRQ(DMA2_Stream4_IRQn);

}
/* FMC initialization function */
static void MX_FMC_Init(void)
{
  FMC_SDRAM_TimingTypeDef SdramTiming;

  /** Perform the SDRAM1 memory initialization sequence
  */
  hsdram1.Instance = FMC_SDRAM_DEVICE;
  /* hsdram1.Init */
  hsdram1.Init.SDBank = FMC_SDRAM_BANK2;
  hsdram1.Init.ColumnBitsNumber = FMC_SDRAM_COLUMN_BITS_NUM_8;
  hsdram1.Init.RowBitsNumber = FMC_SDRAM_ROW_BITS_NUM_12;
  hsdram1.Init.MemoryDataWidth = FMC_SDRAM_MEM_BUS_WIDTH_16;
  hsdram1.Init.InternalBankNumber = FMC_SDRAM_INTERN_BANKS_NUM_4;
  hsdram1.Init.CASLatency = FMC_SDRAM_CAS_LATENCY_3;
  hsdram1.Init.WriteProtection = FMC_SDRAM_WRITE_PROTECTION_DISABLE;
  hsdram1.Init.SDClockPeriod = FMC_SDRAM_CLOCK_PERIOD_2;
  hsdram1.Init.ReadBurst = FMC_SDRAM_RBURST_ENABLE;
  hsdram1.Init.ReadPipeDelay = FMC_SDRAM_RPIPE_DELAY_0;
  /* SdramTiming */
  SdramTiming.LoadToActiveDelay = 2;
  SdramTiming.ExitSelfRefreshDelay = 6;
  SdramTiming.SelfRefreshTime = 4;
  SdramTiming.RowCycleDelay = 6;
  SdramTiming.WriteRecoveryTime = 2;
  SdramTiming.RPDelay = 2;
  SdramTiming.RCDDelay = 2;

  if (HAL_SDRAM_Init(&hsdram1, &SdramTiming) != HAL_OK)
  {
    _Error_Handler(__FILE__, __LINE__);
  }

}

/** Configure pins as
        * Analog
        * Input
        * Output
        * EVENT_OUT
        * EXTI
     PA0/WKUP   ------> ADCx_IN0
     PA1   ------> ADCx_IN1
*/
static void MX_GPIO_Init(void)
{

  GPIO_InitTypeDef GPIO_InitStruct;

  /* GPIO Ports Clock Enable */
  __HAL_RCC_GPIOE_CLK_ENABLE();
  __HAL_RCC_GPIOF_CLK_ENABLE();
  __HAL_RCC_GPIOH_CLK_ENABLE();
  __HAL_RCC_GPIOC_CLK_ENABLE();
  __HAL_RCC_GPIOA_CLK_ENABLE();
  __HAL_RCC_GPIOB_CLK_ENABLE();
  __HAL_RCC_GPIOG_CLK_ENABLE();
  __HAL_RCC_GPIOD_CLK_ENABLE();

  /*Configure GPIO pin Output Level */
  HAL_GPIO_WritePin(Flash_CS_GPIO_Port, Flash_CS_Pin, GPIO_PIN_RESET);

  /*Configure GPIO pin Output Level */
  HAL_GPIO_WritePin(GPIOC, OLED_RST_Pin|OLED_DC_Pin|USB_HOST_PWR_EN_Pin|TR_OUT_A_Pin, GPIO_PIN_RESET);

  /*Configure GPIO pin Output Level */
  HAL_GPIO_WritePin(OLED_CS_GPIO_Port, OLED_CS_Pin, GPIO_PIN_RESET);

  /*Configure GPIO pin Output Level */
  HAL_GPIO_WritePin(TR_OUT_B_GPIO_Port, TR_OUT_B_Pin, GPIO_PIN_RESET);

  /*Configure GPIO pin Output Level */
  HAL_GPIO_WritePin(GPIOG, CS_CS_Pin|CS_RST_Pin, GPIO_PIN_RESET);

  /*Configure GPIO pin : Flash_CS_Pin */
  GPIO_InitStruct.Pin = Flash_CS_Pin;
  GPIO_InitStruct.Mode = GPIO_MODE_OUTPUT_PP;
  GPIO_InitStruct.Pull = GPIO_NOPULL;
  GPIO_InitStruct.Speed = GPIO_SPEED_FREQ_LOW;
  HAL_GPIO_Init(Flash_CS_GPIO_Port, &GPIO_InitStruct);

  /*Configure GPIO pins : OLED_RST_Pin OLED_DC_Pin USB_HOST_PWR_EN_Pin TR_OUT_A_Pin */
  GPIO_InitStruct.Pin = OLED_RST_Pin|OLED_DC_Pin|USB_HOST_PWR_EN_Pin|TR_OUT_A_Pin;
  GPIO_InitStruct.Mode = GPIO_MODE_OUTPUT_PP;
  GPIO_InitStruct.Pull = GPIO_NOPULL;
  GPIO_InitStruct.Speed = GPIO_SPEED_FREQ_LOW;
  HAL_GPIO_Init(GPIOC, &GPIO_InitStruct);

  /*Configure GPIO pins : CV_IN_A_Pin CV_IN_B_Pin */
  GPIO_InitStruct.Pin = CV_IN_A_Pin|CV_IN_B_Pin;
  GPIO_InitStruct.Mode = GPIO_MODE_ANALOG;
  GPIO_InitStruct.Pull = GPIO_NOPULL;
  HAL_GPIO_Init(GPIOA, &GPIO_InitStruct);

  /*Configure GPIO pin : OLED_CS_Pin */
  GPIO_InitStruct.Pin = OLED_CS_Pin;
  GPIO_InitStruct.Mode = GPIO_MODE_OUTPUT_PP;
  GPIO_InitStruct.Pull = GPIO_NOPULL;
  GPIO_InitStruct.Speed = GPIO_SPEED_FREQ_LOW;
  HAL_GPIO_Init(OLED_CS_GPIO_Port, &GPIO_InitStruct);

  /*Configure GPIO pin : USB_HOST_PWR_FAULT_Pin */
  GPIO_InitStruct.Pin = USB_HOST_PWR_FAULT_Pin;
  GPIO_InitStruct.Mode = GPIO_MODE_INPUT;
  GPIO_InitStruct.Pull = GPIO_NOPULL;
  HAL_GPIO_Init(USB_HOST_PWR_FAULT_GPIO_Port, &GPIO_InitStruct);

  /*Configure GPIO pins : TR_IN_B_Pin TR_IN_A_Pin */
  GPIO_InitStruct.Pin = TR_IN_B_Pin|TR_IN_A_Pin;
  GPIO_InitStruct.Mode = GPIO_MODE_IT_RISING_FALLING;
  GPIO_InitStruct.Pull = GPIO_PULLUP;
  HAL_GPIO_Init(GPIOC, &GPIO_InitStruct);

  /*Configure GPIO pin : TR_OUT_B_Pin */
  GPIO_InitStruct.Pin = TR_OUT_B_Pin;
  GPIO_InitStruct.Mode = GPIO_MODE_OUTPUT_PP;
  GPIO_InitStruct.Pull = GPIO_NOPULL;
  GPIO_InitStruct.Speed = GPIO_SPEED_FREQ_LOW;
  HAL_GPIO_Init(TR_OUT_B_GPIO_Port, &GPIO_InitStruct);

  /*Configure GPIO pins : CS_CS_Pin CS_RST_Pin */
  GPIO_InitStruct.Pin = CS_CS_Pin|CS_RST_Pin;
  GPIO_InitStruct.Mode = GPIO_MODE_OUTPUT_PP;
  GPIO_InitStruct.Pull = GPIO_NOPULL;
  GPIO_InitStruct.Speed = GPIO_SPEED_FREQ_LOW;
  HAL_GPIO_Init(GPIOG, &GPIO_InitStruct);

  /*Configure GPIO pin : ENC1_SW_Pin */
  GPIO_InitStruct.Pin = ENC1_SW_Pin;
  GPIO_InitStruct.Mode = GPIO_MODE_IT_FALLING;
  GPIO_InitStruct.Pull = GPIO_PULLUP;
  HAL_GPIO_Init(ENC1_SW_GPIO_Port, &GPIO_InitStruct);

  /*Configure GPIO pin : ENC2_SW_Pin */
  GPIO_InitStruct.Pin = ENC2_SW_Pin;
  GPIO_InitStruct.Mode = GPIO_MODE_IT_FALLING;
  GPIO_InitStruct.Pull = GPIO_PULLUP;
  HAL_GPIO_Init(ENC2_SW_GPIO_Port, &GPIO_InitStruct);

  /* EXTI interrupt init*/
  HAL_NVIC_SetPriority(EXTI4_IRQn, 10, 0);
  HAL_NVIC_EnableIRQ(EXTI4_IRQn);

  HAL_NVIC_SetPriority(EXTI15_10_IRQn, 10, 0);
  HAL_NVIC_EnableIRQ(EXTI15_10_IRQn);

}

/* StartDefaultTask function */
void StartDefaultTask(void const * argument)
{
  /* init code for USB_DEVICE */
  MX_USB_DEVICE_Init();

  /* init code for USB_HOST */
  MX_USB_HOST_Init();

  /* USER CODE BEGIN 5 */
  setup();

  // enable USB Host power
  HAL_GPIO_WritePin(USB_HOST_PWR_EN_GPIO_Port, USB_HOST_PWR_EN_Pin, GPIO_PIN_SET);

  /* Infinite loop */
  for(;;)
  {
    if(HAL_GPIO_ReadPin(USB_HOST_PWR_FAULT_GPIO_Port, USB_HOST_PWR_FAULT_Pin) == GPIO_PIN_RESET){
      HAL_GPIO_WritePin(USB_HOST_PWR_EN_GPIO_Port, USB_HOST_PWR_EN_Pin, GPIO_PIN_RESET);
      error(USB_ERROR, "USB Host PWR fault");
    }else{
      MX_USB_HOST_Process();
    }
    loop();
  }
  /* USER CODE END 5 */
}

void _Error_Handler(char * file, int line)
{
  /* USER CODE BEGIN Error_Handler_Debug */
  /* User can add his own implementation to report the HAL error return state */
#ifdef DEBUG
  __asm__("BKPT");
#else
  NVIC_SystemReset();
#endif
  /* USER CODE END Error_Handler_Debug */
}

#ifdef USE_FULL_ASSERT

/**
   * @brief Reports the name of the source file and the source line number
   * where the assert_param error has occurred.
   * @param file: pointer to the source file name
   * @param line: assert_param error line source number
   * @retval None
   */
void assert_failed(uint8_t* file, uint32_t line)
{
  /* USER CODE BEGIN 6 */
#ifdef DEBUG
  __asm__("BKPT");
#else
  NVIC_SystemReset();
#endif
  /* USER CODE END 6 */

}

#endif

/************************ (C) COPYRIGHT STMicroelectronics *****END OF FILE****/

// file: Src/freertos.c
/**
  ******************************************************************************
  * File Name          : freertos.c
  * Description        : Code for freertos applications
  ******************************************************************************
  * This notice applies to any and all portions of this file
  * that are not between comment pairs USER CODE BEGIN and
  * USER CODE END. Other portions of this file, whether
  * inserted by the user or by software development tools
  * are owned by their respective copyright owners.
  *
  * Copyright (c) 2017 STMicroelectronics International N.V.
  * All rights reserved.
  *
  * Redistribution and use in source and binary forms, with or without
  * modification, are permitted, provided that the following conditions are met:
  *
  * 1. Redistribution of source code must retain the above copyright notice,
  *    this list of conditions and the following disclaimer.
  * 2. Redistributions in binary form must reproduce the above copyright notice,
  *    this list of conditions and the following disclaimer in the documentation
  *    and/or other materials provided with the distribution.
  * 3. Neither the name of STMicroelectronics nor the names of other
  *    contributors to this software may be used to endorse or promote products
  *    derived from this software without specific written permission.
  * 4. This software, including modifications and/or derivative works of this
  *    software, must execute solely and exclusively on microcontroller or
  *    microprocessor devices manufactured by or for STMicroelectronics.
  * 5. Redistribution and use of this software other than as permitted under
  *    this license is void and will automatically terminate your rights under
  *    this license.
  *
  * THIS SOFTWARE IS PROVIDED BY STMICROELECTRONICS AND CONTRIBUTORS "AS IS"
  * AND ANY EXPRESS, IMPLIED OR STATUTORY WARRANTIES, INCLUDING, BUT NOT
  * LIMITED TO, THE IMPLIED WARRANTIES OF MERCHANTABILITY, FITNESS FOR A
  * PARTICULAR PURPOSE AND NON-INFRINGEMENT OF THIRD PARTY INTELLECTUAL PROPERTY
  * RIGHTS ARE DISCLAIMED TO THE FULLEST EXTENT PERMITTED BY LAW. IN NO EVENT
  * SHALL STMICROELECTRONICS OR CONTRIBUTORS BE LIABLE FOR ANY DIRECT, INDIRECT,
  * INCIDENTAL, SPECIAL, EXEMPLARY, OR CONSEQUENTIAL DAMAGES (INCLUDING, BUT NOT
  * LIMITED TO, PROCUREMENT OF SUBSTITUTE GOODS OR SERVICES; LOSS OF USE, DATA,
  * OR PROFITS; OR BUSINESS INTERRUPTION) HOWEVER CAUSED AND ON ANY THEORY OF
  * LIABILITY, WHETHER IN CONTRACT, STRICT LIABILITY, OR TORT (INCLUDING
  * NEGLIGENCE OR OTHERWISE) ARISING IN ANY WAY OUT OF THE USE OF THIS SOFTWARE,
  * EVEN IF ADVISED OF THE POSSIBILITY OF SUCH DAMAGE.
  *
  ******************************************************************************
  */

#include "FreeRTOS.h"
#include "task.h"

/* GetIdleTaskMemory prototype (linked to static allocation support) */
void vApplicationGetIdleTaskMemory( StaticTask_t **ppxIdleTaskTCBBuffer, StackType_t **ppxIdleTaskStackBuffer, uint32_t *pulIdleTaskStackSize );

/* Hook prototypes */
void vApplicationStackOverflowHook(xTaskHandle xTask, signed char *pcTaskName);
void vApplicationMallocFailedHook(void);

/* USER CODE BEGIN 4 */
__weak void vApplicationStackOverflowHook(xTaskHandle xTask, signed char *pcTaskName)
{
   /* Run time stack overflow checking is performed if
   configCHECK_FOR_STACK_OVERFLOW is defined to 1 or 2. This hook function is
   called if a stack overflow is detected. */
}
/* USER CODE END 4 */

/* USER CODE BEGIN 5 */
__weak void vApplicationMallocFailedHook(void)
{
   /* vApplicationMallocFailedHook() will only be called if
   configUSE_MALLOC_FAILED_HOOK is set to 1 in FreeRTOSConfig.h. It is a hook
   function that will get called if a call to pvPortMalloc() fails.
   pvPortMalloc() is called internally by the kernel whenever a task, queue,
   timer or semaphore is created. It is also called by various parts of the
   demo application. If heap_1.c or heap_2.c are used, then the size of the
   heap available to pvPortMalloc() is defined by configTOTAL_HEAP_SIZE in
   FreeRTOSConfig.h, and the xPortGetFreeHeapSize() API function can be used
   to query the size of free heap space that remains (although it does not
   provide information on how the remaining heap might be fragmented). */
}
/* USER CODE END 5 */

/* USER CODE BEGIN GET_IDLE_TASK_MEMORY */
static StaticTask_t xIdleTaskTCBBuffer;
static StackType_t xIdleStack[configMINIMAL_STACK_SIZE];

void vApplicationGetIdleTaskMemory( StaticTask_t **ppxIdleTaskTCBBuffer, StackType_t **ppxIdleTaskStackBuffer, uint32_t *pulIdleTaskStackSize )
{
  *ppxIdleTaskTCBBuffer = &xIdleTaskTCBBuffer;
  *ppxIdleTaskStackBuffer = &xIdleStack[0];
  *pulIdleTaskStackSize = configMINIMAL_STACK_SIZE;
  /* place for user code */
}
/* USER CODE END GET_IDLE_TASK_MEMORY */

/************************ (C) COPYRIGHT STMicroelectronics *****END OF FILE****/
